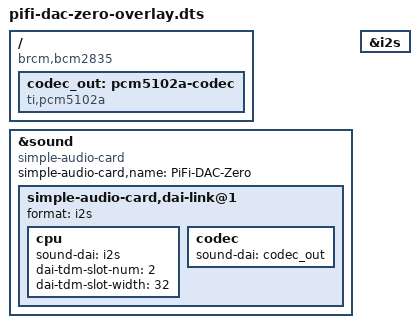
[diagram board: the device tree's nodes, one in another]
// Overlay for PiFi-DAC-Zero
/dts-v1/;
/plugin/;

/ {
	compatible = "brcm,bcm2835";

	fragment@0 {
		target = <&sound>;
		__overlay__ {
			compatible = "simple-audio-card";
			simple-audio-card,name = "PiFi-DAC-Zero";
			status = "okay";

			simple-audio-card,dai-link@1 {
				format = "i2s";

				cpu {
					sound-dai = <&i2s>;
					dai-tdm-slot-num = <2>;
					dai-tdm-slot-width = <32>;
				};

				codec {
					sound-dai = <&codec_out>;
				};
			};
		};
	};

	fragment@1 {
		target-path = "/";
		__overlay__ {
			codec_out: pcm5102a-codec {
				#sound-dai-cells = <0>;
				compatible = "ti,pcm5102a";
				status = "okay";
			};
		};
	};

	fragment@2 {
		target = <&i2s>;
		__overlay__ {
			#sound-dai-cells = <0>;
			status = "okay";
		};
	};
};
